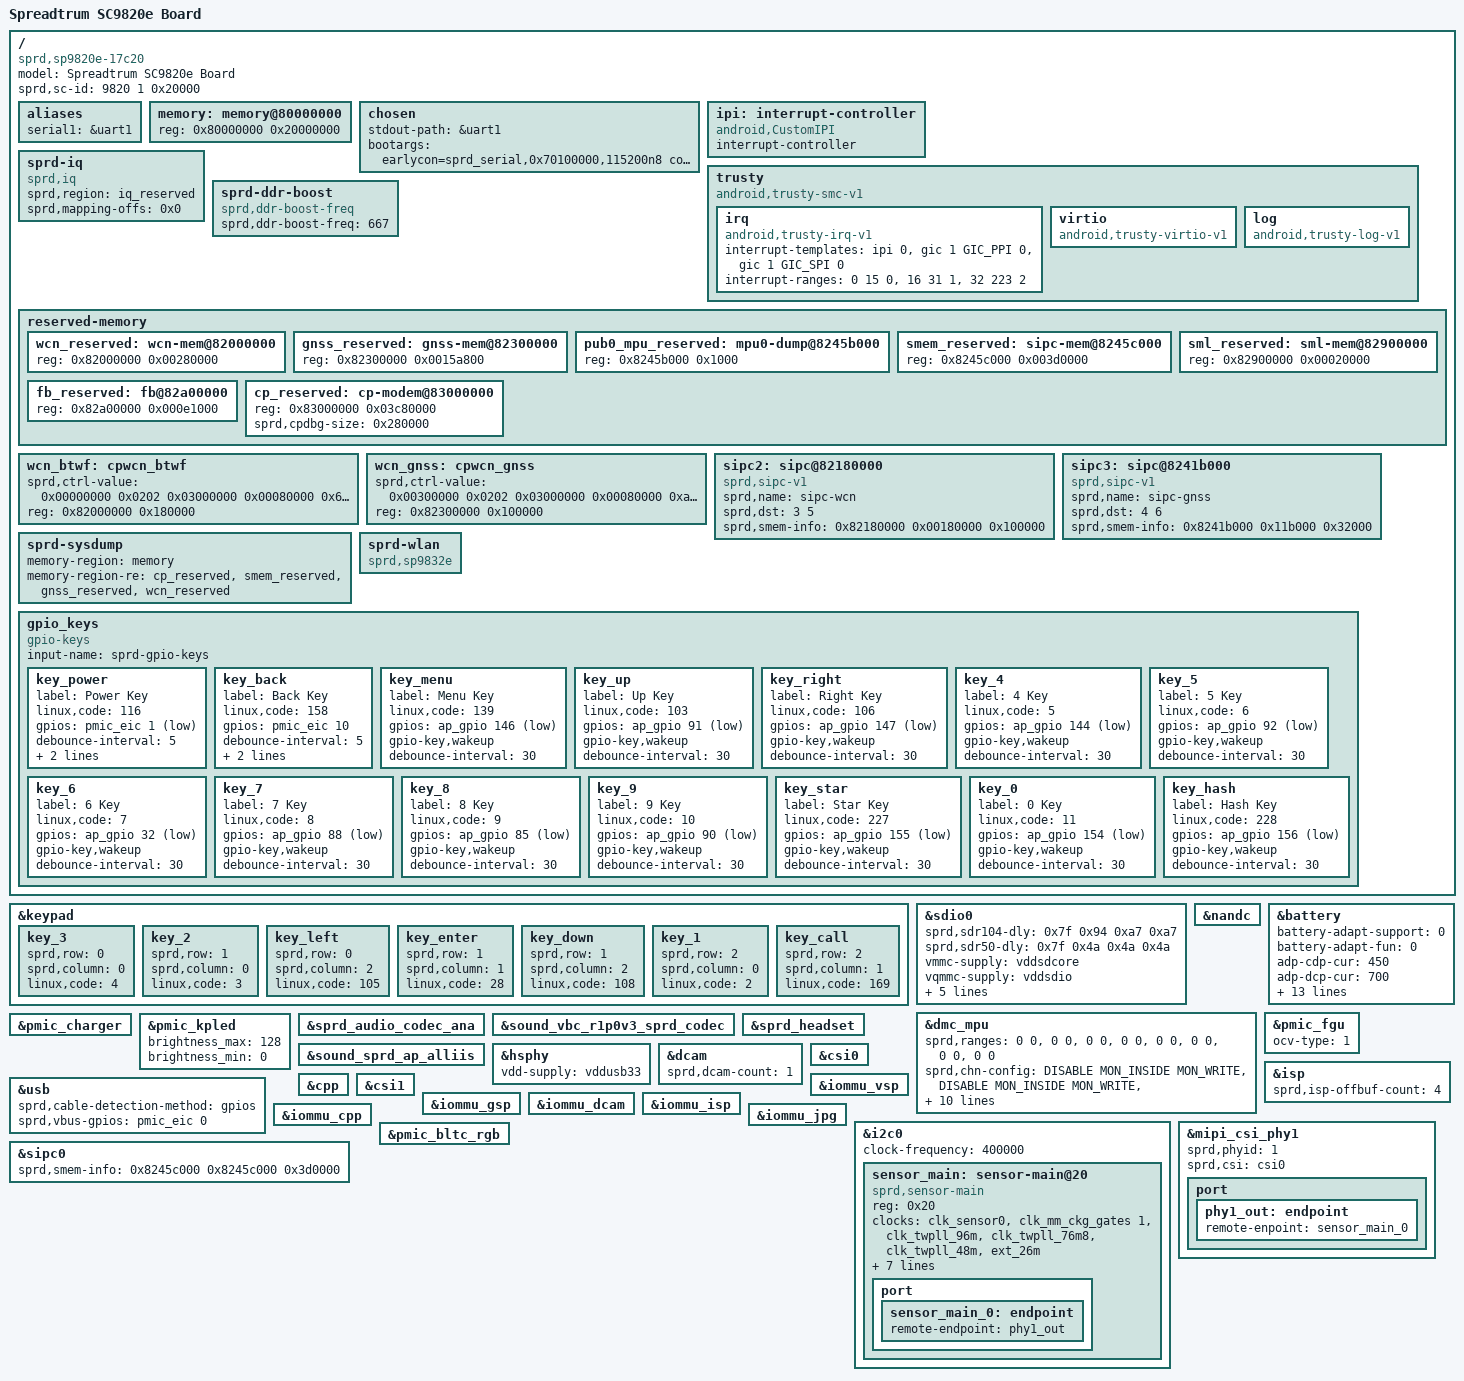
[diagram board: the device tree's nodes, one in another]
/*
 * Spreadtrum sharkle sp9820e board DTS file
 *
 * Copyright (C) 2017, Spreadtrum Communications Inc.
 *
 * This file is licensed under a dual GPLv2 or X11 license.
 */
/dts-v1/;

#include "sc9820e.dtsi"
#include "sp9820e-common.dtsi"

/ {
	model = "Spreadtrum SC9820e Board";

	compatible = "sprd,sp9820e-17c20", "sprd,sc9820e";

	sprd,sc-id = <9820 1 0x20000>;

	aliases {
		serial1 = &uart1;
	};

	memory: memory@80000000 {
		device_type = "memory";
		reg = <0x80000000 0x20000000>;
	};

	chosen {
		stdout-path = &uart1;
		bootargs = "earlycon=sprd_serial,0x70100000,115200n8 console=ttyS1,115200n8 loglevel=7 init=/init root=/dev/ram0 rw androidboot.hardware=sp9820e_17c20";
	};

	ipi: interrupt-controller {
		compatible = "android,CustomIPI";
		#interrupt-cells = <1>;
		interrupt-controller;
	};

	trusty {
		compatible = "android,trusty-smc-v1";

		irq {
			compatible = "android,trusty-irq-v1";
			interrupt-templates = <&ipi 0>,
						<&gic 1 GIC_PPI 0>,
						<&gic 1 GIC_SPI 0>;
			interrupt-ranges = < 0  15 0>,
						<16  31 1>,
						<32 223 2>;
		};

		virtio {
			compatible = "android,trusty-virtio-v1";
		};

		log {
			compatible = "android,trusty-log-v1";
		};
	};

	sprd-iq {
		compatible = "sprd,iq";
		sprd,region = <&iq_reserved>;
		sprd,mapping-offs = <0x0>;
	};

	sprd-ddr-boost {
		compatible = "sprd,ddr-boost-freq";
		sprd,ddr-boost-freq = <667>;
	};

	reserved-memory {
		/delete-node/ mpu0-dump@877ff000;
		/delete-node/ sipc-mem@87800000;
		/delete-node/ wcn-mem@88000000;
		/delete-node/ gnss-mem@88300000;
		/delete-node/ cp-modem@89600000;
		/delete-node/ sml-mem@8e000000;
		/delete-node/ fb@8fb3e000;
		/delete-node/ sysdump-uboot@9f000000;
                /delete-node/ tos-mem@8e100000;
		/* must be 32M aligned */
		wcn_reserved: wcn-mem@82000000{
			reg = <0x82000000 0x00280000>;
		};
		gnss_reserved: gnss-mem@82300000{
			reg = <0x82300000 0x0015a800>;
		};
		pub0_mpu_reserved: mpu0-dump@8245b000 {
			reg = <0x8245b000 0x1000>;
		};
		smem_reserved: sipc-mem@8245c000 {
			reg = <0x8245c000 0x003d0000>;
		};
		/* must be 1M aligned */
		sml_reserved: sml-mem@82900000{
			reg = <0x82900000 0x00020000>;
		};
		fb_reserved: fb@82a00000{
			reg = <0x82a00000 0x000e1000>;
		};
		/* cp_reserved = cp region + debug region */
		/* debug region: not reserved in normal mode, it */
		/* will be proccessed in u-boot */
		cp_reserved: cp-modem@83000000 {
			reg = <0x83000000 0x03c80000>;
		/* This prop specifies the size of debug region */
		/* in the cp tail */
			sprd,cpdbg-size = <0x280000>;
		};

	};

	/* WCN base mem adjust */
	wcn_btwf: cpwcn_btwf {    /* <WCN_BTWF_START_ADDR> */
		sprd,ctrl-value = <0x00000000 0x0202 0x03000000
				  0x00080000 0x600 0x80>;
		reg = <0x82000000 0x180000>;
	};

	/* gnss base mem adjust */
	wcn_gnss: cpwcn_gnss {    /* <WCN_GNSS_START_ADDR> */
		sprd,ctrl-value = <0x00300000 0x0202 0x03000000
				   0x00080000 0xa00 0x40>;
		reg = <0x82300000 0x100000>;
	};

	/* wcn sipc mem adjust */
	/delete-node/ sipc@88180000;
	sipc2: sipc@82180000 {
		compatible = "sprd,sipc-v1";
		sprd,name = "sipc-wcn";
		sprd,dst = <3 5>; /* <dst core-id> */
		/* <ap-addr dst-maped-addr size> */
		sprd,smem-info = <0x82180000 0x00180000 0x100000>;
	};

	/* gnss sipc mem adjust */
	/delete-node/ sipc@8841b000;
	sipc3: sipc@8241b000 {
		compatible = "sprd,sipc-v1";
		sprd,name = "sipc-gnss";
		sprd,dst = <4 6>; /* <dst core-id> */
		/* <ap-addr dst-maped-addr size> */
		sprd,smem-info = <0x8241b000 0x11b000 0x32000>;
	};

	sprd-sysdump {
		memory-region = <&memory>;
		memory-region-re = <&cp_reserved>, <&smem_reserved>,
				<&gnss_reserved>, <&wcn_reserved>;
	};

	sprd-wlan {
		 compatible = "sprd,sp9832e";
	};

	gpio_keys {
		compatible = "gpio-keys";
		input-name = "sprd-gpio-keys";
		status = "ok";

		key_power {
			label = "Power Key";
			linux,code = <116>;
			gpios = <&pmic_eic 1 1>;
			debounce-interval = <5>;
			gpio-key,wakeup;
			gpio-key,level-trigger;
		};
		key_back {
			label = "Back Key";
			linux,code = <158>;
			gpios = <&pmic_eic 10 0>;
			debounce-interval = <5>;
			gpio-key,wakeup;
			gpio-key,level-trigger;
		};
		key_menu {
			label = "Menu Key";
			linux,code = <139>;
			gpios = <&ap_gpio 146 1>;
			gpio-key,wakeup;
			debounce-interval = <30>;
		};
		key_up {
			label = "Up Key";
			linux,code = <103>;
			gpios = <&ap_gpio 91 1>;
			gpio-key,wakeup;
			debounce-interval = <30>;
		};
		key_right {
			label = "Right Key";
			linux,code = <106>;
			gpios = <&ap_gpio 147 1>;
			gpio-key,wakeup;
			debounce-interval = <30>;
		};
		key_4 {
			label = "4 Key";
			linux,code = <5>;
			gpios = <&ap_gpio 144 1>;
			gpio-key,wakeup;
			debounce-interval = <30>;
		};
		key_5 {
			label = "5 Key";
			linux,code = <6>;
			gpios = <&ap_gpio 92 1>;
			gpio-key,wakeup;
			debounce-interval = <30>;
		};
		key_6 {
			label = "6 Key";
			linux,code = <7>;
			gpios = <&ap_gpio 32 1>;
			gpio-key,wakeup;
			debounce-interval = <30>;
		};
		key_7 {
			label = "7 Key";
			linux,code = <8>;
			gpios = <&ap_gpio 88 1>;
			gpio-key,wakeup;
			debounce-interval = <30>;
		};
		key_8 {
			label = "8 Key";
			linux,code = <9>;
			gpios = <&ap_gpio 85 1>;
			gpio-key,wakeup;
			debounce-interval = <30>;
		};
		key_9 {
			label = "9 Key";
			linux,code = <10>;
			gpios = <&ap_gpio 90 1>;
			gpio-key,wakeup;
			debounce-interval = <30>;
		};
		key_star {
			label = "Star Key";
			linux,code = <227>;
			gpios = <&ap_gpio 155 1>;
			gpio-key,wakeup;
			debounce-interval = <30>;
		};
		key_0 {
			label = "0 Key";
			linux,code = <11>;
			gpios = <&ap_gpio 154 1>;
			gpio-key,wakeup;
			debounce-interval = <30>;
		};
		key_hash {
			label = "Hash Key";
			linux,code = <228>;
			gpios = <&ap_gpio 156 1>;
			gpio-key,wakeup;
			debounce-interval = <30>;
		};
	};
};

&keypad {
	status = "okay";
	key_3 {
		sprd,row = <0>;
		sprd,column = <0>;
		linux,code = <4>;
	};
	key_2 {
		sprd,row = <1>;
		sprd,column = <0>;
		linux,code = <3>;
	};
	key_left {
		sprd,row = <0>;
		sprd,column = <2>;
		linux,code = <105>;
	};
	key_enter {
		sprd,row = <1>;
		sprd,column = <1>;
		linux,code = <28>;
	};
	key_down {
		sprd,row = <1>;
		sprd,column = <2>;
		linux,code = <108>;
	};
	key_1 {
		sprd,row = <2>;
		sprd,column = <0>;
		linux,code = <2>;
	};
	key_call {
		sprd,row = <2>;
		sprd,column = <1>;
		linux,code = <169>;
	};
};

&sdio0 {
	sprd,sdr104-dly = <0x7f 0x94 0xa7 0xa7>;
	sprd,sdr50-dly = <0x7f 0x4a 0x4a 0x4a>;
	vmmc-supply = <&vddsdcore>;
	vqmmc-supply = <&vddsdio>;
	voltage-ranges = <3000 3000>;
	bus-width = <4>;
	sprd,name = "sdio_sd";
	no-sdio;
	no-mmc;
	status = "okay";
};

&nandc {
	status = "okay";
};

&dmc_mpu {
	sprd,ranges =
			<0 0>,
			<0 0>,
			<0 0>,
			<0 0>,
			<0 0>,
			<0 0>,
			<0 0>,
			<0 0>;
	sprd,chn-config =
			<DISABLE MON_INSIDE MON_WRITE>,
			<DISABLE MON_INSIDE MON_WRITE>,
			<DISABLE MON_INSIDE MON_WRITE>,
			<DISABLE MON_INSIDE MON_WRITE>,
			<DISABLE MON_INSIDE MON_WRITE>,
			<DISABLE MON_INSIDE MON_WRITE>,
			<DISABLE MON_OUTSIDE MON_WRITE>,
			<DISABLE MON_INSIDE MON_WRITE>;
	sprd,id-config =
			<MPUID 0 0>, <MPUID 0 0>,
			<MPUID 0 0>, <MPUID 0 0>,
			<MPUID 0 0>, <MPUID 0 0>,
			<MPUID 0 0>, <MPUID 0 0>;
	sprd,shared-chn = "MM";
	status = "ok";
};

&battery {
	battery-adapt-support = <0>;
	battery-adapt-fun = <0>;
	adp-cdp-cur = <450>;
	adp-dcp-cur = <700>;
	adp-sdp-cur = <450>;
	adp-unknown-cur = <450>;
	chg-end-vol = <4200>;
	chg-end-vol-check = <4180>;
	chg-bat-safety-vol = <4230>;
	rechg-vol = <4120>;
	rsense-real = <200>;
	rint = <238>;
	cnom = <1700>;
	ocv-tab-vol = <4183 4117 4073 4044 4024 3993 3960
			3929 3896 3860 3832 3809 3790 3778
			3772 3764 3741 3701 3624 3552 3400>;
	ocv-tab-cap = <100  95   90   85   80   75   70
			65   60   55   50   45   40   35
			30   25   20   15   10   5   0>;
};

&pmic_fgu {
	ocv-type = <1>;
};

&pmic_charger {
	status = "okay";
};

&pmic_kpled {
	brightness_max = <128>;
	brightness_min = <0>;
	status = "okay";
};

&sprd_audio_codec_ana {
	status = "okay";
};

&sound_vbc_r1p0v3_sprd_codec {
	status = "okay";
};

&sound_sprd_ap_alliis {
	status = "okay";
};

&sprd_headset {
	status = "okay";
};

&hsphy {
	vdd-supply = <&vddusb33>;
};

&usb {
	sprd,cable-detection-method = "gpios";
	sprd,vbus-gpios = <&pmic_eic 0 0>;
};

&dcam {
	status = "okay";
	sprd,dcam-count = <1>;
};

&isp {
	sprd,isp-offbuf-count = <4>;
	status = "okay";
};

&csi0 {
	status = "okay";
};

&cpp {
	status = "okay";
};

&csi1 {
	status = "okay";
};

&iommu_vsp {
	status = "okay";
};
&iommu_gsp {
	status = "okay";
};

&iommu_dcam {
	status = "okay";
};

&iommu_isp {
	status = "okay";
};

&iommu_cpp {
	status = "okay";
};

&iommu_jpg {
	status = "okay";
};

&i2c0 {
	status = "okay";
	clock-frequency = <400000>;

	sensor_main: sensor-main@20 {
		compatible = "sprd,sensor-main";
		reg = <0x20>;
		clock-names = "clk_src","sensor_eb",
			"clk_96m","clk_76m8",
			"clk_48m","clk_26m";
		clocks = <&clk_sensor0>, <&clk_mm_ckg_gates 1>,
			<&clk_twpll_96m>,<&clk_twpll_76m8>,
			<&clk_twpll_48m>,<&ext_26m>;
		vddio-supply = <&vddcamio>;
		vddcama-supply = <&vddcama>;
		vddcamd-supply = <&vddcamd>;
		vddcammot-supply = <&vddcammot>;
		reset-gpios = <&ap_gpio 45 0>;
		power-down-gpios = <&ap_gpio 47 0>;
		host = "dcam0";
		port {
			sensor_main_0: endpoint {
				remote-endpoint = <&phy1_out>;
			};
		};
	};
};

&mipi_csi_phy1 {
	status = "okay";
	sprd,phyid = <1>;
	sprd,csi = <&csi0>;
	port {
	phy1_out: endpoint {
		remote-enpoint = <&sensor_main_0>;
		};
	};
};

&pmic_bltc_rgb {
	status = "okay";
};

&sipc0 {
	sprd,smem-info = <0x8245c000 0x8245c000 0x3d0000>;
};
